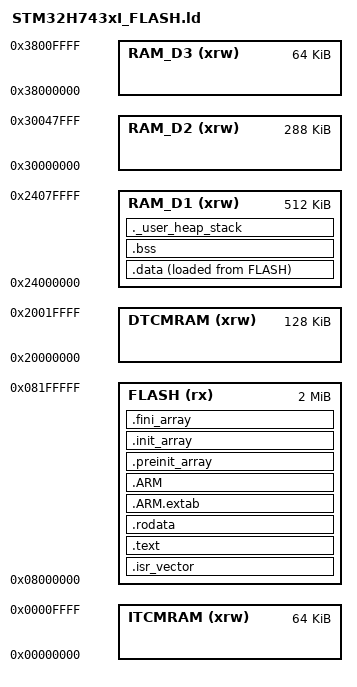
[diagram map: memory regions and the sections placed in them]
/* STM32H743xI (2 MB flash / 1 MB RAM) -- execute from flash.
 *
 * NOTE ON RAM CHOICE: .data/.bss/heap/stack live in AXI SRAM (RAM_D1), not in
 * DTCMRAM as ST's stock template does. DTCM is faster but is NOT reachable by
 * the DMA controllers on the H7 -- putting buffers there is the single most
 * common source of "my DMA silently does nothing" bugs. Starting in AXI SRAM
 * keeps every sensor DMA buffer valid by default. Move to DTCMRAM later only
 * for hot, CPU-only data.
 */

ENTRY(Reset_Handler)

MEMORY
{
  ITCMRAM (xrw) : ORIGIN = 0x00000000, LENGTH = 64K
  FLASH   (rx)  : ORIGIN = 0x08000000, LENGTH = 2048K
  DTCMRAM (xrw) : ORIGIN = 0x20000000, LENGTH = 128K
  RAM_D1  (xrw) : ORIGIN = 0x24000000, LENGTH = 512K   /* AXI SRAM  */
  RAM_D2  (xrw) : ORIGIN = 0x30000000, LENGTH = 288K   /* SRAM1/2/3 */
  RAM_D3  (xrw) : ORIGIN = 0x38000000, LENGTH = 64K    /* SRAM4     */
}

REGION_ALIAS("RAM", RAM_D1);

_estack     = ORIGIN(RAM) + LENGTH(RAM);  /* stack grows down from the top */
_Min_Heap_Size  = 0x200;   /* newlib heap; FreeRTOS uses its own heap_4 pool */
_Min_Stack_Size = 0x800;   /* startup/ISR stack, before the scheduler runs   */

SECTIONS
{
  .isr_vector :
  {
    . = ALIGN(4);
    KEEP(*(.isr_vector))
    . = ALIGN(4);
  } >FLASH

  .text :
  {
    . = ALIGN(4);
    *(.text)
    *(.text*)
    *(.glue_7)
    *(.glue_7t)
    *(.eh_frame)
    KEEP(*(.init))
    KEEP(*(.fini))
    . = ALIGN(4);
    _etext = .;
  } >FLASH

  .rodata :
  {
    . = ALIGN(4);
    *(.rodata)
    *(.rodata*)
    . = ALIGN(4);
  } >FLASH

  .ARM.extab : { *(.ARM.extab* .gnu.linkonce.armextab.*) } >FLASH
  .ARM : {
    __exidx_start = .;
    *(.ARM.exidx*)
    __exidx_end = .;
  } >FLASH

  .preinit_array :
  {
    PROVIDE_HIDDEN(__preinit_array_start = .);
    KEEP(*(.preinit_array*))
    PROVIDE_HIDDEN(__preinit_array_end = .);
  } >FLASH

  .init_array :
  {
    PROVIDE_HIDDEN(__init_array_start = .);
    KEEP(*(SORT(.init_array.*)))
    KEEP(*(.init_array*))
    PROVIDE_HIDDEN(__init_array_end = .);
  } >FLASH

  .fini_array :
  {
    PROVIDE_HIDDEN(__fini_array_start = .);
    KEEP(*(SORT(.fini_array.*)))
    KEEP(*(.fini_array*))
    PROVIDE_HIDDEN(__fini_array_end = .);
  } >FLASH

  /* Flash image of .data, copied into RAM by Reset_Handler. */
  _sidata = LOADADDR(.data);

  .data :
  {
    . = ALIGN(4);
    _sdata = .;
    *(.data)
    *(.data*)
    . = ALIGN(4);
    _edata = .;
  } >RAM AT >FLASH

  .bss :
  {
    . = ALIGN(4);
    _sbss = .;
    __bss_start__ = _sbss;
    *(.bss)
    *(.bss*)
    *(COMMON)
    . = ALIGN(4);
    _ebss = .;
    __bss_end__ = _ebss;
  } >RAM

  /* Link-time proof that the heap and stack still fit. */
  ._user_heap_stack :
  {
    . = ALIGN(8);
    PROVIDE(end = .);
    PROVIDE(_end = .);
    . = . + _Min_Heap_Size;
    . = . + _Min_Stack_Size;
    . = ALIGN(8);
  } >RAM

  /DISCARD/ :
  {
    libc.a(*)
    libm.a(*)
    libgcc.a(*)
  }

  .ARM.attributes 0 : { *(.ARM.attributes) }
}
